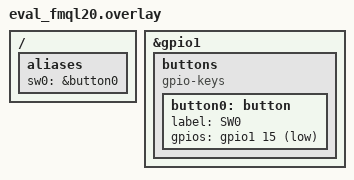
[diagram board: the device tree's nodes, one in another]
#include <zephyr/dt-bindings/gpio/gpio.h>

/ {
	aliases {
		sw0 = &button0;
	};
};

&gpio1 {
	status = "okay";
	buttons {
		compatible = "gpio-keys";
		status = "okay";
		button0: button {
			label = "SW0";
			gpios = <&gpio1 15 GPIO_ACTIVE_LOW>; // MIO47 SD Detect pin
		};
	};
};
